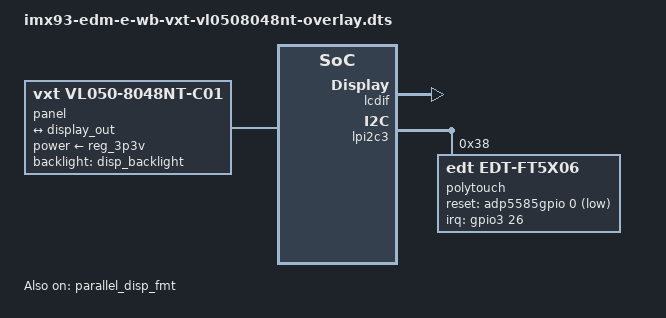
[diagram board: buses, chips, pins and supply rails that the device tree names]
// SPDX-License-Identifier: (GPL-2.0+ OR MIT)
/*
 * Copyright 2024 TechNexion Ltd.
 *
 * Author: Alex Fang <alex.fang@technexion.com>
 *
 */

/dts-v1/;
/plugin/;

#include <dt-bindings/interrupt-controller/irq.h>
#include <dt-bindings/gpio/gpio.h>

/ {
	fragment@0 {
		target-path = "/";
		__overlay__ {
			disp_backlight: disp_backlight {
				post-pwm-on-delay-ms = <500>;
				enable-gpios = <&adp5585gpio 4 GPIO_ACTIVE_HIGH>; //LCD0_BLT_EN
				status = "okay";
			};
		};
	};

	fragment@1 {
		target-path = "/";
		__overlay__ {
			panel {
				compatible = "vxt,vl050-8048nt-c01";
				backlight = <&disp_backlight>;
				power-supply = <&reg_3p3v>;

				port {
					panel_in: endpoint {
						remote-endpoint = <&display_out>;
					};
				};
			};
		};
	};

	fragment@2 {
		target = <&parallel_disp_fmt>;
		__overlay__ {
			pinctrl-names = "default";
			pinctrl-0 = <&pinctrl_lcdif>;
			fsl,interface-pix-fmt = "rgb888";
			status = "okay";

			ports {
				#address-cells = <1>;
				#size-cells = <0>;
				port@1 {
					reg = <1>;

					display_out: endpoint {
						remote-endpoint = <&panel_in>;
					};
				};
			};
		};
	};

	fragment@3 {
		target = <&lcdif>;
		__overlay__ {
			status = "okay";
		};
	};

	fragment@4 {
		target = <&lpi2c3>;
		__overlay__ {
			#address-cells = <1>;
			#size-cells = <0>;
			status = "okay";

			polytouch: edt-ft5x06@38 {
				pinctrl-names = "default";
				pinctrl-0 = <&pinctrl_i2ctouch1>;
				compatible = "edt,edt-ft5x06";
				reg = <0x38>;
				interrupt-parent = <&gpio3>;
				interrupts = <26 IRQ_TYPE_LEVEL_LOW>;
				reset-gpios = <&adp5585gpio 0 GPIO_ACTIVE_LOW>;
				touchscreen-size-x = <800>;
				touchscreen-size-y = <480>;
			};
		};
	};
};
